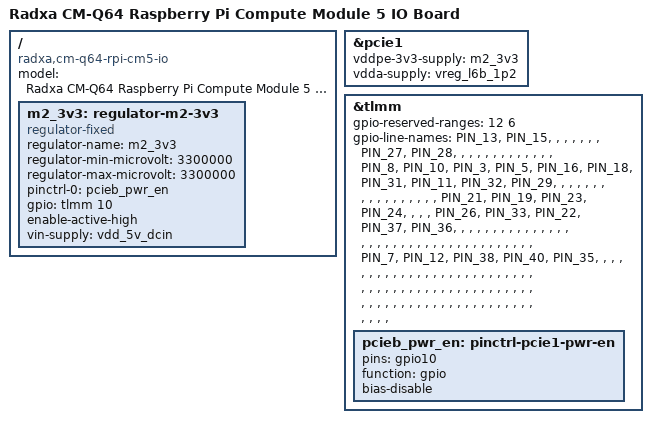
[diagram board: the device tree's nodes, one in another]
// SPDX-License-Identifier: BSD-3-Clause
/*
 * Copyright (c) 2025 Radxa Computer (Shenzhen) Co., Ltd.
 */

/dts-v1/;

#include "qcs6490-radxa-cm-q64.dtsi"

/ {
	model = "Radxa CM-Q64 Raspberry Pi Compute Module 5 IO Board";
	compatible = "radxa,cm-q64-rpi-cm5-io", "radxa,cm-q64", "qcom,qcm6490";

	m2_3v3: regulator-m2-3v3 {
		compatible = "regulator-fixed";
		regulator-name = "m2_3v3";
		regulator-min-microvolt = <3300000>;
		regulator-max-microvolt = <3300000>;
		pinctrl-names = "default";
		pinctrl-0 = <&pcieb_pwr_en>;
		gpio = <&tlmm 10 GPIO_ACTIVE_HIGH>;
		enable-active-high;
		vin-supply = <&vdd_5v_dcin>;
	};
};

&pcie1 {
	vddpe-3v3-supply = <&m2_3v3>;
	vdda-supply = <&vreg_l6b_1p2>;
};

&tlmm {
	/*
	 * 12-17: reserved for QSPI flash
	 */
	gpio-reserved-ranges = <12 6>;
	gpio-line-names =
		/* GPIO_0 ~ GPIO_3 */
		"PIN_13", "PIN_15", "", "",
		/* GPIO_4 ~ GPIO_7 */
		"", "", "", "",
		/* GPIO_8 ~ GPIO_11 */
		"PIN_27", "PIN_28", "", "",
		/* GPIO_12 ~ GPIO_15 */
		"", "", "", "",
		/* GPIO_16 ~ GPIO_19 */
		"", "", "", "",
		/* GPIO_20 ~ GPIO_23 */
		"", "", "PIN_8", "PIN_10",
		/* GPIO_24 ~ GPIO_27 */
		"PIN_3", "PIN_5", "PIN_16", "PIN_18",
		/* GPIO_28 ~ GPIO_31 */
		"PIN_31", "PIN_11", "PIN_32", "PIN_29",
		/* GPIO_32 ~ GPIO_35 */
		"", "", "", "",
		/* GPIO_36 ~ GPIO_39 */
		"", "", "", "",
		/* GPIO_40 ~ GPIO_43 */
		"", "", "", "",
		/* GPIO_44 ~ GPIO_47 */
		"", "", "", "",
		/* GPIO_48 ~ GPIO_51 */
		"PIN_21", "PIN_19", "PIN_23", "PIN_24",
		/* GPIO_52 ~ GPIO_55 */
		"", "", "", "PIN_26",
		/* GPIO_56 ~ GPIO_59 */
		"PIN_33", "PIN_22", "PIN_37", "PIN_36",
		/* GPIO_60 ~ GPIO_63 */
		"", "", "", "",
		/* GPIO_64 ~ GPIO_67 */
		"", "", "", "",
		/* GPIO_68 ~ GPIO_71 */
		"", "", "", "",
		/* GPIO_72 ~ GPIO_75 */
		"", "", "", "",
		/* GPIO_76 ~ GPIO_79 */
		"", "", "", "",
		/* GPIO_80 ~ GPIO_83 */
		"", "", "", "",
		/* GPIO_84 ~ GPIO_87 */
		"", "", "", "",
		/* GPIO_88 ~ GPIO_91 */
		"", "", "", "",
		/* GPIO_92 ~ GPIO_95 */
		"", "", "", "",
		/* GPIO_96 ~ GPIO_99 */
		"PIN_7", "PIN_12", "PIN_38", "PIN_40",
		/* GPIO_100 ~ GPIO_103 */
		"PIN_35", "", "", "",
		/* GPIO_104 ~ GPIO_107 */
		"", "", "", "",
		/* GPIO_108 ~ GPIO_111 */
		"", "", "", "",
		/* GPIO_112 ~ GPIO_115 */
		"", "", "", "",
		/* GPIO_116 ~ GPIO_119 */
		"", "", "", "",
		/* GPIO_120 ~ GPIO_123 */
		"", "", "", "",
		/* GPIO_124 ~ GPIO_127 */
		"", "", "", "",
		/* GPIO_128 ~ GPIO_131 */
		"", "", "", "",
		/* GPIO_132 ~ GPIO_135 */
		"", "", "", "",
		/* GPIO_136 ~ GPIO_139 */
		"", "", "", "",
		/* GPIO_140 ~ GPIO_143 */
		"", "", "", "",
		/* GPIO_144 ~ GPIO_147 */
		"", "", "", "",
		/* GPIO_148 ~ GPIO_151 */
		"", "", "", "",
		/* GPIO_152 ~ GPIO_155 */
		"", "", "", "",
		/* GPIO_156 ~ GPIO_159 */
		"", "", "", "",
		/* GPIO_160 ~ GPIO_163 */
		"", "", "", "",
		/* GPIO_164 ~ GPIO_167 */
		"", "", "", "",
		/* GPIO_168 ~ GPIO_171 */
		"", "", "", "",
		/* GPIO_172 ~ GPIO_174 */
		"", "", "";

	pcieb_pwr_en: pinctrl-pcie1-pwr-en {
		pins = "gpio10";
		function = "gpio";
		bias-disable;
	};
};
